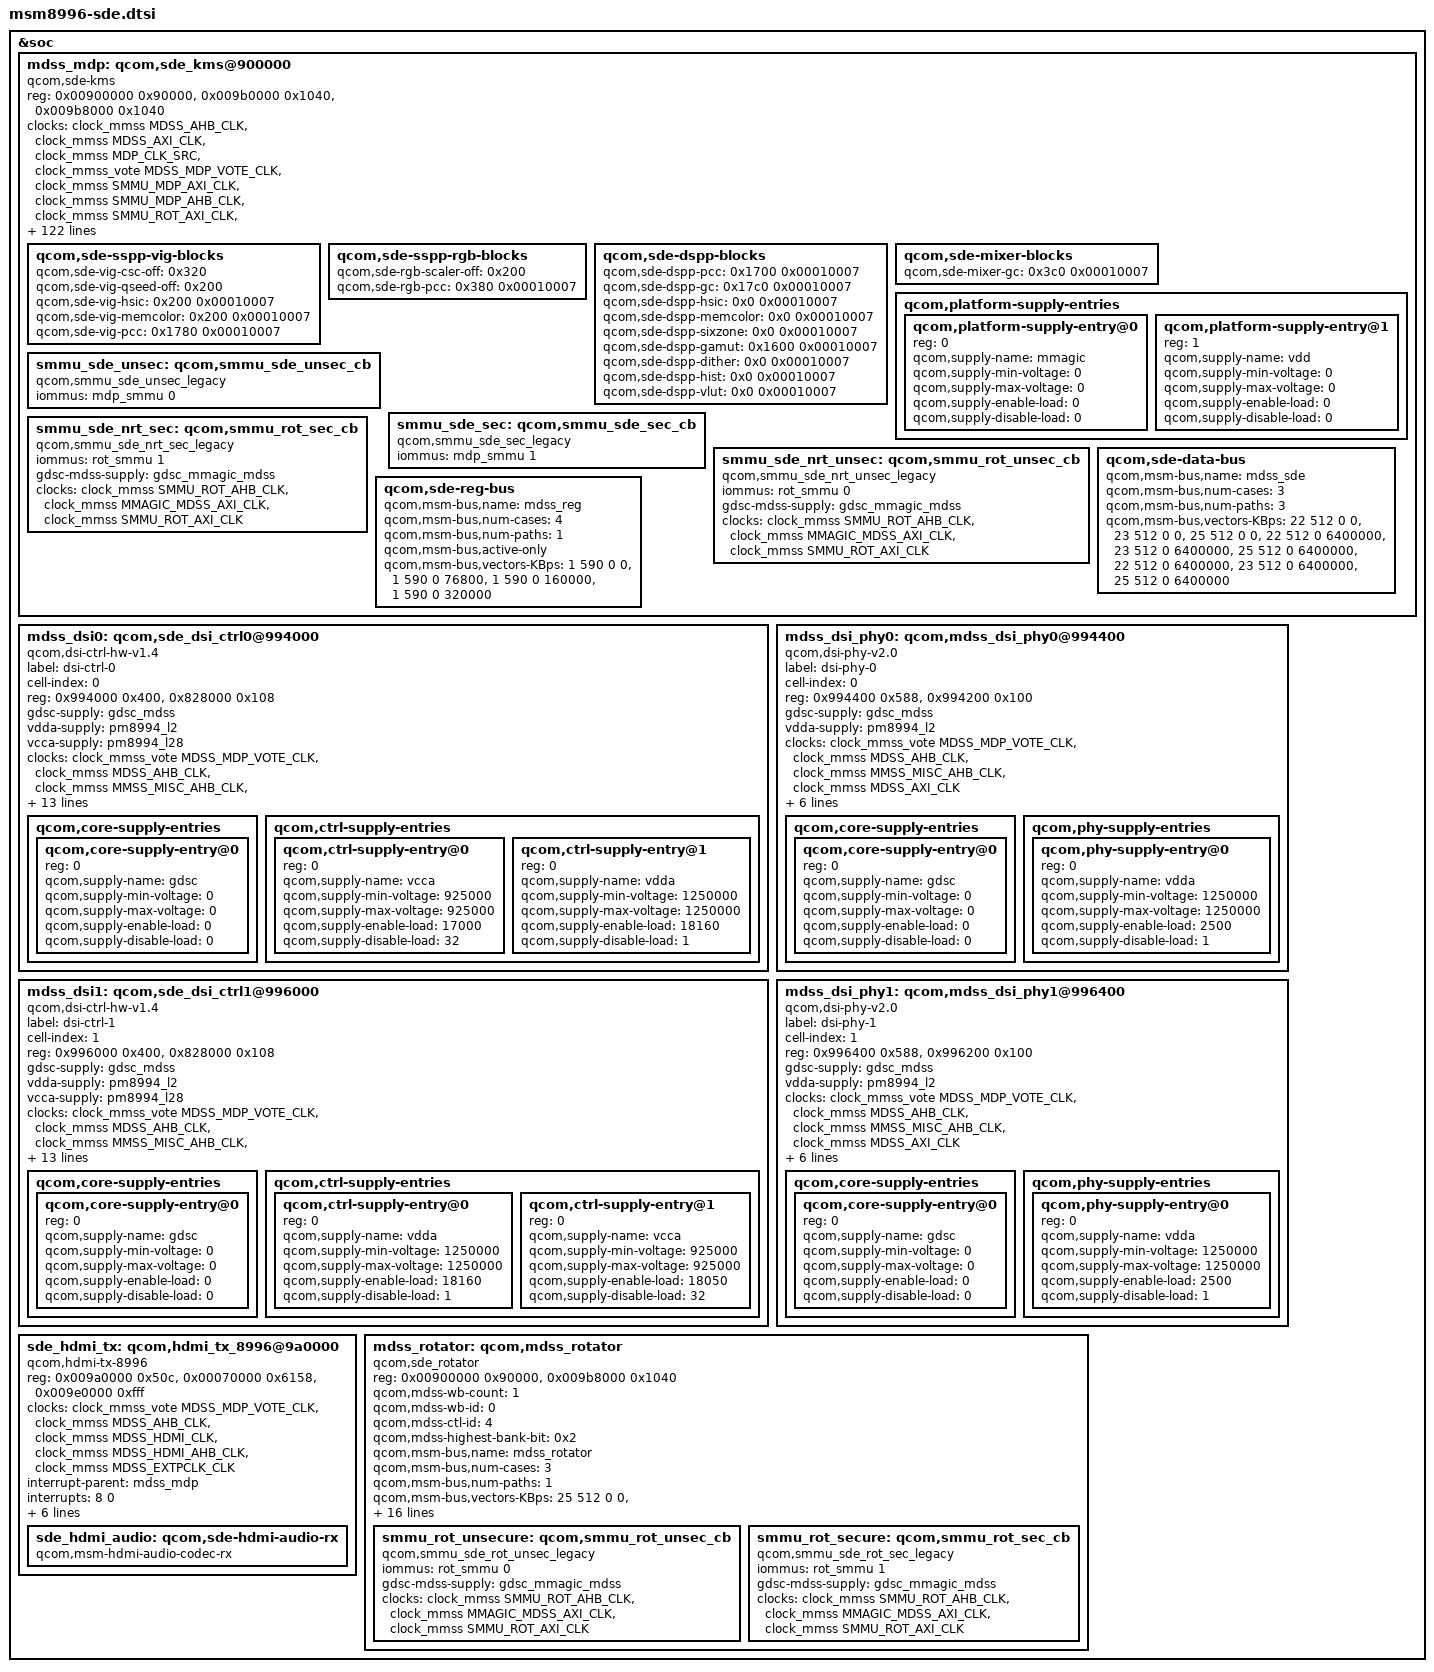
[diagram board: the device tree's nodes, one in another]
/* Copyright (c) 2016-2017, The Linux Foundation. All rights reserved.
 *
 * This program is free software; you can redistribute it and/or modify
 * it under the terms of the GNU General Public License version 2 and
 * only version 2 as published by the Free Software Foundation.
 *
 * This program is distributed in the hope that it will be useful,
 * but WITHOUT ANY WARRANTY; without even the implied warranty of
 * MERCHANTABILITY or FITNESS FOR A PARTICULAR PURPOSE.  See the
 * GNU General Public License for more details.
 */

&soc {
	mdss_mdp: qcom,sde_kms@900000 {
		compatible = "qcom,sde-kms";
		reg = <0x00900000 0x90000>,
		      <0x009b0000 0x1040>,
		      <0x009b8000 0x1040>;
		reg-names = "mdp_phys",
			"vbif_phys",
			"vbif_nrt_phys";

		/* clock and supply entries */
		clocks = <&clock_mmss MDSS_AHB_CLK>,
			 <&clock_mmss MDSS_AXI_CLK>,
			 <&clock_mmss MDP_CLK_SRC>,
			 <&clock_mmss_vote MDSS_MDP_VOTE_CLK>,
			 <&clock_mmss SMMU_MDP_AXI_CLK>,
			 <&clock_mmss SMMU_MDP_AHB_CLK>,
			 <&clock_mmss SMMU_ROT_AXI_CLK>,
			 <&clock_mmss SMMU_ROT_AHB_CLK>,
			 <&clock_mmss MMAGIC_MDSS_AXI_CLK>,
			 <&clock_mmss MDSS_VSYNC_CLK>;
		clock-names = "iface_clk",
			"bus_clk",
			"core_clk_src",
			"core_clk",
			"iommu_mdp_axi_clk",
			"iommu_mdp_ahb_clk",
			"iommu_rot_axi_clk",
			"iommu_rot_ahb_clk",
			"mmagic_clk",
			"vsync_clk";
		clock-rate = <0 0 412500000 412500000 0 0 0 0 0 19200000>;
		clock-max-rate = <0 0 412500000 412500000 0 0 0 0 0 19200000>;

		/* interrupt config */
		interrupt-parent = <&intc>;
		interrupts = <0 83 0>;
		interrupt-controller;
		#interrupt-cells = <1>;
		iommus = <&mdp_smmu 0>;

		#address-cells = <1>;
		#size-cells = <0>;

		#power-domain-cells = <0>;

		//gpus = <&msm_gpu>;

		/* hw blocks */
		qcom,sde-off = <0x1000>;
		qcom,sde-len = <0x454>;

		qcom,sde-ctl-off = <0x2000 0x2200 0x2400
				     0x2600 0x2800>;
		qcom,sde-ctl-size = <0x64>;
		qcom,sde-ctl-display-pref = "primary", "primary", "none",
						"none", "none";

		qcom,sde-mixer-off = <0x45000 0x46000 0x47000
				      0x48000 0x49000 0x4a000>;
		qcom,sde-mixer-size = <0x2bc>;
		qcom,sde-mixer-display-pref = "primary", "primary", "none",
						"none", "none", "none";

		qcom,sde-dspp-top-off = <0x1300>;
		qcom,sde-dspp-top-size = <0xc>;

		qcom,sde-dspp-off = <0x55000 0x57000>;
		qcom,sde-dspp-size = <0x22c>;
		//qcom,sde-dspp-size = <0x17e0>;

		qcom,sde-dspp-ad-off = <0x24000 0x22800>;
		qcom,sde-dspp-ad-version = <0x00030000>;

		qcom,sde-wb-off = <0x66000>;
		qcom,sde-wb-size = <0x2c0>;

		qcom,sde-wb-id = <2>;
		qcom,sde-wb-xin-id = <6>;
		qcom,sde-wb-clk-ctrl = <0x2bc 16>;

		qcom,sde-intf-off = <0x6b000 0x6b800
					0x6c000 0x6c800>;
		qcom,sde-intf-size = <0x268>;

		qcom,sde-intf-type = "none", "dsi", "dsi", "hdmi";
		qcom,sde-pp-off = <0x71000 0x71800
					  0x72000 0x72800 0x73000>;
		qcom,sde-pp-slave = <0x0 0x0 0x0 0x0 0x1>;
		qcom,sde-pp-size = <0xd4>;

		qcom,sde-te2-off = <0x2000 0x2000 0x0 0x0 0x0>;

		qcom,sde-cdm-off = <0x7a200>;
		qcom,sde-cdm-size = <0x224>;

		qcom,sde-dsc-off = <0x10000 0x10000 0x0 0x0 0x0>;
		qcom,sde-dsc-size = <0x140>;

/*
		qcom,sde-dither-off = <0x30e0 0x30e0 0x30e0 0x30e0 0x0>;
		qcom,sde-dither-version = <0x00010000>;
		qcom,sde-dither-size = <0x20>;
*/

		qcom,sde-intf-max-prefetch-lines = <0x15 0x15 0x15 0x15>;

		qcom,sde-sspp-type = "vig", "vig", "vig",
				      "vig", "rgb", "rgb",
				      "rgb", "rgb", "dma",
				      "dma";

		qcom,sde-sspp-off = <0x5000 0x7000 0x9000
				      0xb000 0x15000 0x17000
				      0x19000 0x1b000 0x25000
				      0x27000>;
		qcom,sde-sspp-src-size = <0x150>;

		qcom,sde-sspp-xin-id = <0 4 8
					12 1 5
					9 13 2
					10>;

		qcom,sde-mixer-pair-mask = <2 1 6 0 0 3>;
		qcom,sde-mixer-blend-op-off = <0x20 0x50 0x80 0xb0
					       0x230 0x260 0x290>;

		/* offsets are relative to "mdp_phys + qcom,sde-off */
		qcom,sde-sspp-clk-ctrl = <0x2ac 0>, <0x2b4 0>, <0x2bc 0>,
				  <0x2c4 0>, <0x2ac 4>, <0x2b4 4>, <0x2bc 4>,
				  <0x2c4 4>, <0x2ac 8>, <0x2b4 8>;
		qcom,sde-qseed-type = "qseedv3";
		qcom,sde-csc-type = "csc";
		qcom,sde-mixer-linewidth = <2560>;
		qcom,sde-sspp-linewidth = <2560>;
		qcom,sde-wb-linewidth = <4096>;
		qcom,sde-mixer-blendstages = <0x7>;
		qcom,sde-highest-bank-bit = <0x2>;
		qcom,sde-panic-per-pipe;
		qcom,sde-has-cdp;
		qcom,sde-has-src-split;
		//qcom,sde-has-idle-pc;
		qcom,sde-has-dest-scaler;
		qcom,sde-max-dest-scaler-input-linewidth = <2048>;
		qcom,sde-max-dest-scaler-output-linewidth = <2560>;
		qcom,sde-max-per-pipe-bw-kbps = <4500000>;
		qcom,sde-max-bw-low-kbps = <9600000>;
		qcom,sde-max-bw-high-kbps = <9600000>;
		qcom,sde-min-core-ib-kbps = <2400000>;
		qcom,sde-min-llcc-ib-kbps = <800000>;
		qcom,sde-min-dram-ib-kbps = <800000>;
		qcom,sde-dram-channels = <2>;
		qcom,sde-num-nrt-paths = <1>;

		/* VBIF QoS remapper settings*/
		qcom,sde-vbif-qos-rt-remap = <1 2 2 2>;
		qcom,sde-vbif-qos-nrt-remap = <1 1 1 1>;
		qcom,sde-cdp-setting = <1 1>, <1 0>;

		qcom,sde-danger-lut = <0x0000000f 0x0000ffff 0x00000000
			0x00000000>;
		qcom,sde-safe-lut-linear =
			<0 0xfffc>;
		qcom,sde-safe-lut-macrotile =
			<0 0xff00>;
		qcom,sde-safe-lut-nrt =
			<0 0xffff>;
		qcom,sde-safe-lut-cwb =
			<0 0xffff>;

		qcom,sde-qos-lut-linear =
			<4 0x00000000 0x0000001B>,
			<5 0x00000000 0x0000005B>,
			<6 0x00000000 0x0000015B>,
			<7 0x00000000 0x0000055B>,
			<8 0x00000000 0x0000155B>,
			<9 0x00000000 0x0000555B>,
			<10 0x00000000 0x0001555B>,
			<11 0x00000000 0x0005555B>,
			<12 0x00000000 0x0015555B>,
			<13 0x00000000 0x0055555B>,
			<14 0x00000000 0x00000000>,
			<1 0x00000000 0x0000001B>,
			<0 0x00000000 0x00000000>;
		qcom,sde-qos-lut-macrotile =
			<10 0x00000000 0x0001AAFF>,
			<11 0x00000000 0x0005AAFF>,
			<12 0x00000000 0x0015AAFF>,
			<13 0x00000000 0x0055AAFF>,
			<1  0x00000000 0x0001AAFF>,
			<0  0x00000000 0x00000000>;
		qcom,sde-qos-lut-nrt =
			<0 0x00000000 0x00000000>;
		qcom,sde-qos-lut-cwb =
			<0 0x00000000 0x00000000>;

		qcom,sde-vbif-off = <0 0>;
		qcom,sde-vbif-size = <0x1040>;
		qcom,sde-vbif-id = <0 1>;
		qcom,sde-vbif-default-ot-rd-limit = <32>;
		qcom,sde-vbif-default-ot-wr-limit = <16>;
/*
		qcom,sde-vbif-dynamic-ot-rd-limit = <62208000 2>,
			<124416000 4>, <248832000 16>;
		qcom,sde-vbif-dynamic-ot-wr-limit = <62208000 2>,
			<124416000 4>, <248832000 16>;
*/
		mmagic-supply = <&gdsc_mmagic_mdss>;
		vdd-supply = <&gdsc_mdss>;

		qcom,sde-sspp-vig-blocks {
			qcom,sde-vig-csc-off = <0x320>;
			qcom,sde-vig-qseed-off = <0x200>;
			/* Offset from vig top, version of HSIC */
			qcom,sde-vig-hsic = <0x200 0x00010007>;
			qcom,sde-vig-memcolor = <0x200 0x00010007>;
			qcom,sde-vig-pcc = <0x1780 0x00010007>;
		};

		qcom,sde-sspp-rgb-blocks {
			qcom,sde-rgb-scaler-off = <0x200>;
			qcom,sde-rgb-pcc = <0x380 0x00010007>;
		};

		qcom,sde-dspp-blocks {
			qcom,sde-dspp-pcc = <0x1700 0x00010007>;
			qcom,sde-dspp-gc = <0x17c0 0x00010007>;
			qcom,sde-dspp-hsic = <0x0 0x00010007>;
			qcom,sde-dspp-memcolor = <0x0 0x00010007>;
			qcom,sde-dspp-sixzone = <0x0 0x00010007>;
			qcom,sde-dspp-gamut = <0x1600 0x00010007>;
			qcom,sde-dspp-dither = <0x0 0x00010007>;
			qcom,sde-dspp-hist = <0x0 0x00010007>;
			qcom,sde-dspp-vlut = <0x0 0x00010007>;
		};

		qcom,sde-mixer-blocks {
			qcom,sde-mixer-gc = <0x3c0 0x00010007>;
		};

		qcom,platform-supply-entries {
			#address-cells = <1>;
			#size-cells = <0>;

			qcom,platform-supply-entry@0 {
				reg = <0>;
				qcom,supply-name = "mmagic";
				qcom,supply-min-voltage = <0>;
				qcom,supply-max-voltage = <0>;
				qcom,supply-enable-load = <0>;
				qcom,supply-disable-load = <0>;
			};

			qcom,platform-supply-entry@1 {
				reg = <1>;
				qcom,supply-name = "vdd";
				qcom,supply-min-voltage = <0>;
				qcom,supply-max-voltage = <0>;
				qcom,supply-enable-load = <0>;
				qcom,supply-disable-load = <0>;
			};
		};

		smmu_sde_unsec: qcom,smmu_sde_unsec_cb {
			compatible = "qcom,smmu_sde_unsec_legacy";
			iommus = <&mdp_smmu 0>;
		};

		smmu_sde_sec: qcom,smmu_sde_sec_cb {
			compatible = "qcom,smmu_sde_sec_legacy";
			iommus = <&mdp_smmu 1>;
		};

		smmu_sde_nrt_unsec: qcom,smmu_rot_unsec_cb {
			compatible = "qcom,smmu_sde_nrt_unsec_legacy";
			iommus = <&rot_smmu 0>;
			gdsc-mdss-supply = <&gdsc_mmagic_mdss>;
			clocks = <&clock_mmss SMMU_ROT_AHB_CLK>,
				<&clock_mmss MMAGIC_MDSS_AXI_CLK>,
				<&clock_mmss SMMU_ROT_AXI_CLK>;
			clock-names = "rot_ahb_clk", "mmagic_mdss_axi_clk",
				"rot_axi_clk";
		};

		smmu_sde_nrt_sec: qcom,smmu_rot_sec_cb {
			compatible = "qcom,smmu_sde_nrt_sec_legacy";
			iommus = <&rot_smmu 1>;
			gdsc-mdss-supply = <&gdsc_mmagic_mdss>;
			clocks = <&clock_mmss SMMU_ROT_AHB_CLK>,
				<&clock_mmss MMAGIC_MDSS_AXI_CLK>,
				<&clock_mmss SMMU_ROT_AXI_CLK>;
			clock-names = "rot_ahb_clk", "mmagic_mdss_axi_clk",
				"rot_axi_clk";
		};

		/* data and reg bus scale settings */
		qcom,sde-data-bus {
			qcom,msm-bus,name = "mdss_sde";
			qcom,msm-bus,num-cases = <3>;
			qcom,msm-bus,num-paths = <3>;
			qcom,msm-bus,vectors-KBps =
				<22 512 0 0>, <23 512 0 0>, <25 512 0 0>,
				<22 512 0 6400000>, <23 512 0 6400000>,
					<25 512 0 6400000>,
				<22 512 0 6400000>, <23 512 0 6400000>,
					<25 512 0 6400000>;
		};

		qcom,sde-reg-bus {
			qcom,msm-bus,name = "mdss_reg";
			qcom,msm-bus,num-cases = <4>;
			qcom,msm-bus,num-paths = <1>;
			qcom,msm-bus,active-only;
			qcom,msm-bus,vectors-KBps =
				<1 590 0 0>,
				<1 590 0 76800>,
				<1 590 0 160000>,
				<1 590 0 320000>;
		};
	};

	mdss_dsi0: qcom,sde_dsi_ctrl0@994000 {
		compatible = "qcom,dsi-ctrl-hw-v1.4";
		label = "dsi-ctrl-0";
		cell-index = <0>;
		reg =   <0x994000 0x400>,
			<0x828000 0x108>;
		reg-names = "dsi_ctrl", "mmss_misc";

		gdsc-supply = <&gdsc_mdss>;
		vdda-supply = <&pm8994_l2>;
		vcca-supply = <&pm8994_l28>;

		clocks = <&clock_mmss_vote MDSS_MDP_VOTE_CLK>,
			 <&clock_mmss MDSS_AHB_CLK>,
			 <&clock_mmss MMSS_MISC_AHB_CLK>,
			 <&clock_mmss MDSS_AXI_CLK>,
			 <&clock_mmss MDSS_BYTE0_CLK>,
			 <&clock_mmss MDSS_PCLK0_CLK>,
			 <&clock_mmss MDSS_ESC0_CLK>,
			 <&clock_mmss BYTE0_CLK_SRC>,
			 <&clock_mmss PCLK0_CLK_SRC>;

		clock-names = "mdp_core_clk", "iface_clk",
			"core_mmss_clk", "bus_clk",
			"byte_clk", "pixel_clk", "esc_clk",
			"byte_clk_rcg", "pixel_clk_rcg";

		/* axi bus scale settings */
		qcom,msm-bus,name = "mdss_dsi0";
		qcom,msm-bus,num-cases = <2>;
		qcom,msm-bus,num-paths = <1>;
		qcom,msm-bus,vectors-KBps =
			<22 512 0 0>,
			<22 512 0 1000>;

		interrupt-parent = <&mdss_mdp>;
		interrupts = <4 0>;
		qcom,core-supply-entries {
			#address-cells = <1>;
			#size-cells = <0>;

			qcom,core-supply-entry@0 {
				reg = <0>;
				qcom,supply-name = "gdsc";
				qcom,supply-min-voltage = <0>;
				qcom,supply-max-voltage = <0>;
				qcom,supply-enable-load = <0>;
				qcom,supply-disable-load = <0>;
			};
		};

		qcom,ctrl-supply-entries {
			#address-cells = <1>;
			#size-cells = <0>;

			qcom,ctrl-supply-entry@0 {
				reg = <0>;
				qcom,supply-name = "vcca";
				qcom,supply-min-voltage = <925000>;
				qcom,supply-max-voltage = <925000>;
				qcom,supply-enable-load = <17000>;
				qcom,supply-disable-load = <32>;
			};

			qcom,ctrl-supply-entry@1 {
				reg = <0>;
				qcom,supply-name = "vdda";
				qcom,supply-min-voltage = <1250000>;
				qcom,supply-max-voltage = <1250000>;
				qcom,supply-enable-load = <18160>;
				qcom,supply-disable-load = <1>;
			};

		};
	};

	mdss_dsi1: qcom,sde_dsi_ctrl1@996000 {
		compatible = "qcom,dsi-ctrl-hw-v1.4";
		label = "dsi-ctrl-1";
		cell-index = <1>;
		reg =   <0x996000 0x400>,
			<0x828000 0x108>;
		reg-names = "dsi_ctrl", "mmss_misc";

		gdsc-supply = <&gdsc_mdss>;
		vdda-supply = <&pm8994_l2>;
		vcca-supply = <&pm8994_l28>;

		clocks = <&clock_mmss_vote MDSS_MDP_VOTE_CLK>,
			 <&clock_mmss MDSS_AHB_CLK>,
			 <&clock_mmss MMSS_MISC_AHB_CLK>,
			 <&clock_mmss MDSS_AXI_CLK>,
			 <&clock_mmss MDSS_BYTE1_CLK>,
			 <&clock_mmss MDSS_PCLK1_CLK>,
			 <&clock_mmss MDSS_ESC1_CLK>,
			 <&clock_mmss BYTE1_CLK_SRC>,
			 <&clock_mmss PCLK1_CLK_SRC>;
		clock-names = "mdp_core_clk", "iface_clk",
			"core_mmss_clk", "bus_clk",
			"byte_clk", "pixel_clk", "esc_clk",
			"byte_clk_rcg", "pixel_clk_rcg";

		/* axi bus scale settings */
		qcom,msm-bus,name = "mdss_dsi1";
		qcom,msm-bus,num-cases = <2>;
		qcom,msm-bus,num-paths = <1>;
		qcom,msm-bus,vectors-KBps =
			<22 512 0 0>,
			<22 512 0 1000>;

		interrupt-parent = <&mdss_mdp>;
		interrupts = <5 0>;
		qcom,core-supply-entries {
			#address-cells = <1>;
			#size-cells = <0>;

			qcom,core-supply-entry@0 {
				reg = <0>;
				qcom,supply-name = "gdsc";
				qcom,supply-min-voltage = <0>;
				qcom,supply-max-voltage = <0>;
				qcom,supply-enable-load = <0>;
				qcom,supply-disable-load = <0>;
			};
		};

		qcom,ctrl-supply-entries {
			#address-cells = <1>;
			#size-cells = <0>;

			qcom,ctrl-supply-entry@0 {
				reg = <0>;
				qcom,supply-name = "vdda";
				qcom,supply-min-voltage = <1250000>;
				qcom,supply-max-voltage = <1250000>;
				qcom,supply-enable-load = <18160>;
				qcom,supply-disable-load = <1>;
			};

			qcom,ctrl-supply-entry@1 {
				reg = <0>;
				qcom,supply-name = "vcca";
				qcom,supply-min-voltage = <925000>;
				qcom,supply-max-voltage = <925000>;
				qcom,supply-enable-load = <18050>;
				qcom,supply-disable-load = <32>;
			};
		};
	};

	mdss_dsi_phy0: qcom,mdss_dsi_phy0@994400 {
		compatible = "qcom,dsi-phy-v2.0";
		label = "dsi-phy-0";
		cell-index = <0>;
		reg = <0x994400 0x588>, <0x994200 0x100>;
		reg-names = "dsi_phy", "dyn_refresh_base";

		gdsc-supply = <&gdsc_mdss>;
		vdda-supply = <&pm8994_l2>;

		clocks = <&clock_mmss_vote MDSS_MDP_VOTE_CLK>,
			 <&clock_mmss MDSS_AHB_CLK>,
			 <&clock_mmss MMSS_MISC_AHB_CLK>,
			 <&clock_mmss MDSS_AXI_CLK>;
		clock-names = "mdp_core_clk", "iface_clk",
			"core_mmss_clk", "bus_clk";

		qcom,platform-strength-ctrl = [ff 06
						ff 06
						ff 06
						ff 06
						ff 00];
		qcom,platform-regulator-settings = [1d
						1d 1d 1d 1d];
		qcom,platform-lane-config = [00 00 10 0f
					00 00 10 0f
					00 00 10 0f
					00 00 10 0f
					00 00 10 8f];

		qcom,core-supply-entries {
			#address-cells = <1>;
			#size-cells = <0>;

			qcom,core-supply-entry@0 {
				reg = <0>;
				qcom,supply-name = "gdsc";
				qcom,supply-min-voltage = <0>;
				qcom,supply-max-voltage = <0>;
				qcom,supply-enable-load = <0>;
				qcom,supply-disable-load = <0>;
			};
		};

		qcom,phy-supply-entries {
			#address-cells = <1>;
			#size-cells = <0>;

			qcom,phy-supply-entry@0 {
				reg = <0>;
				qcom,supply-name = "vdda";
				qcom,supply-min-voltage = <1250000>;
				qcom,supply-max-voltage = <1250000>;
				qcom,supply-enable-load = <2500>;
				qcom,supply-disable-load = <1>;
			};
		};
	};

	mdss_dsi_phy1: qcom,mdss_dsi_phy1@996400 {
		compatible = "qcom,dsi-phy-v2.0";
		label = "dsi-phy-1";
		cell-index = <1>;
		reg = <0x996400 0x588>, <0x996200 0x100>;
		reg-names = "dsi_phy", "dyn_refresh_base";

		gdsc-supply = <&gdsc_mdss>;
		vdda-supply = <&pm8994_l2>;

		clocks = <&clock_mmss_vote MDSS_MDP_VOTE_CLK>,
			 <&clock_mmss MDSS_AHB_CLK>,
			 <&clock_mmss MMSS_MISC_AHB_CLK>,
			 <&clock_mmss MDSS_AXI_CLK>;
		clock-names = "mdp_core_clk", "iface_clk",
			"core_mmss_clk", "bus_clk";

		qcom,platform-strength-ctrl = [ff 06
						ff 06
						ff 06
						ff 06
						ff 00];
		qcom,platform-regulator-settings = [1d
						1d 1d 1d 1d];
		qcom,platform-lane-config = [00 00 10 0f
					00 00 10 0f
					00 00 10 0f
					00 00 10 0f
					00 00 10 8f];

		qcom,core-supply-entries {
			#address-cells = <1>;
			#size-cells = <0>;

			qcom,core-supply-entry@0 {
				reg = <0>;
				qcom,supply-name = "gdsc";
				qcom,supply-min-voltage = <0>;
				qcom,supply-max-voltage = <0>;
				qcom,supply-enable-load = <0>;
				qcom,supply-disable-load = <0>;
			};
		};

		qcom,phy-supply-entries {
			#address-cells = <1>;
			#size-cells = <0>;

			qcom,phy-supply-entry@0 {
				reg = <0>;
				qcom,supply-name = "vdda";
				qcom,supply-min-voltage = <1250000>;
				qcom,supply-max-voltage = <1250000>;
				qcom,supply-enable-load = <2500>;
				qcom,supply-disable-load = <1>;
			};
		};
	};

	sde_hdmi_tx: qcom,hdmi_tx_8996@9a0000 {
		compatible = "qcom,hdmi-tx-8996";

		reg =	<0x009a0000 0x50c>,
			<0x00070000 0x6158>,
			<0x009e0000 0xfff>;
		reg-names = "core_physical",
			"qfprom_physical",
			"hdcp_physical";
		clocks = <&clock_mmss_vote MDSS_MDP_VOTE_CLK>,
			 <&clock_mmss MDSS_AHB_CLK>,
			 <&clock_mmss MDSS_HDMI_CLK>,
			 <&clock_mmss MDSS_HDMI_AHB_CLK>,
			 <&clock_mmss MDSS_EXTPCLK_CLK>;
		clock-names =
			"mdp_core_clk",
			"iface_clk",
			"core_clk",
			"alt_iface_clk",
			"extp_clk";
		interrupt-parent = <&mdss_mdp>;
		interrupts = <8 0>;
		hpd-gdsc-supply = <&gdsc_mdss>;
		qcom,hdmi-tx-hpd-gpio = <&pm8994_mpps 4 0>;
		pinctrl-names = "default", "sleep";
		pinctrl-0 = <&mdss_hdmi_hpd_active
			     &mdss_hdmi_ddc_active
			     &mdss_hdmi_cec_active>;
		pinctrl-1 = <&mdss_hdmi_hpd_suspend
			     &mdss_hdmi_ddc_suspend
			     &mdss_hdmi_cec_suspend>;

		sde_hdmi_audio: qcom,sde-hdmi-audio-rx {
			compatible = "qcom,msm-hdmi-audio-codec-rx";
		};
	};


	mdss_rotator: qcom,mdss_rotator {
		compatible = "qcom,sde_rotator";
		reg = <0x00900000 0x90000>,
		      <0x009b8000 0x1040>;
		reg-names = "mdp_phys",
			"rot_vbif_phys";

		#list-cells = <1>;

		qcom,mdss-wb-count = <1>;
		qcom,mdss-wb-id = <0>;
		qcom,mdss-ctl-id = <4>;
		qcom,mdss-highest-bank-bit = <0x2>;
		/* Bus Scale Settings */
		qcom,msm-bus,name = "mdss_rotator";
		qcom,msm-bus,num-cases = <3>;
		qcom,msm-bus,num-paths = <1>;
		qcom,msm-bus,vectors-KBps =
			<25 512 0 0>,
			<25 512 0 6400000>,
			<25 512 0 6400000>;

		rot-vdd-supply = <&gdsc_mdss>;
		rot-mmagic-mdss-gdsc-supply = <&gdsc_mmagic_mdss>;

		qcom,supply-names = "rot-mmagic-mdss-gdsc", "rot-vdd";

		clocks = <&clock_mmss MMSS_MISC_AHB_CLK>,
			<&clock_mmss_vote MDSS_ROTATOR_VOTE_CLK>,
			<&clock_mmss MDSS_AHB_CLK>,
			<&clock_mmss MDSS_AXI_CLK>,
			<&clock_mmss MDP_CLK_SRC>;
		clock-names = "mnoc_clk", "rot_core_clk",
			"iface_clk", "axi_clk", "rot_clk";


		interrupt-parent = <&mdss_mdp>;
		interrupts = <2 0>;

		power-domains = <&mdss_mdp>;

		/* VBIF QoS remapper settings*/
		qcom,mdss-rot-vbif-qos-setting = <1 1 1 1>;

		qcom,mdss-default-ot-rd-limit = <32>;
		qcom,mdss-default-ot-wr-limit = <16>;

		smmu_rot_unsecure: qcom,smmu_rot_unsec_cb {
			compatible = "qcom,smmu_sde_rot_unsec_legacy";
			iommus = <&rot_smmu 0>;
			gdsc-mdss-supply = <&gdsc_mmagic_mdss>;
			clocks = <&clock_mmss SMMU_ROT_AHB_CLK>,
				<&clock_mmss MMAGIC_MDSS_AXI_CLK>,
				<&clock_mmss SMMU_ROT_AXI_CLK>;
			clock-names = "rot_ahb_clk", "mmagic_mdss_axi_clk",
				"rot_axi_clk";
		};

		smmu_rot_secure: qcom,smmu_rot_sec_cb {
			compatible = "qcom,smmu_sde_rot_sec_legacy";
			iommus = <&rot_smmu 1>;
			gdsc-mdss-supply = <&gdsc_mmagic_mdss>;
			clocks = <&clock_mmss SMMU_ROT_AHB_CLK>,
				<&clock_mmss MMAGIC_MDSS_AXI_CLK>,
				<&clock_mmss SMMU_ROT_AXI_CLK>;
			clock-names = "rot_ahb_clk", "mmagic_mdss_axi_clk",
				"rot_axi_clk";
		};
	};
};
